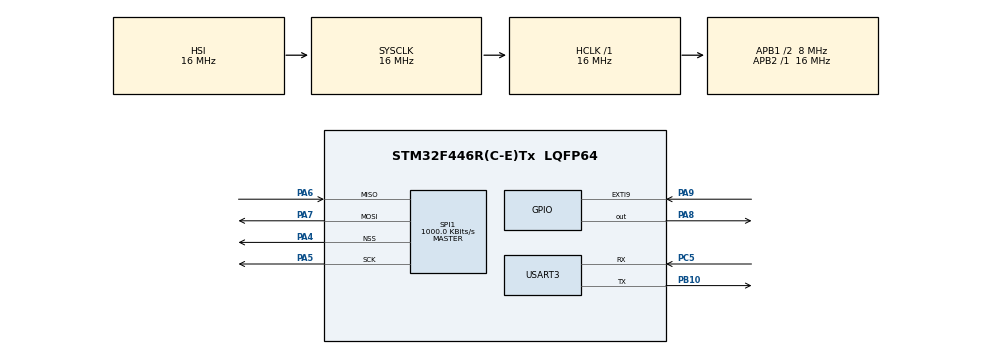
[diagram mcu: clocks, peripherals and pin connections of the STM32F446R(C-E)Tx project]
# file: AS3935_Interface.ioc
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Mcu.Family=STM32F4
Mcu.Name=STM32F446R(C-E)Tx
Mcu.Package=LQFP64
NVIC.EXTI9_5_IRQn=true\:0\:0\:false\:false\:true\:true\:true
NVIC.PriorityGroup=NVIC_PRIORITYGROUP_0
PA13.GPIO_Label=TMS
PA13.Mode=Serial_Wire
PA13.Signal=SYS_JTMS-SWDIO
PA14.GPIO_Label=TCK
PA14.Mode=Serial_Wire
PA14.Signal=SYS_JTCK-SWCLK
PA2.GPIO_Label=USART_TX
PA2.Signal=USART2_TX
PA3.GPIO_Label=USART_RX
PA3.Signal=USART2_RX
PA4.Mode=NSS_Signal_Hard_Output
PA4.Signal=SPI1_NSS
PA5.Mode=Full_Duplex_Master
PA5.Signal=SPI1_SCK
PA6.Mode=Full_Duplex_Master
PA6.Signal=SPI1_MISO
PA7.Mode=Full_Duplex_Master
PA7.Signal=SPI1_MOSI
PA8.Signal=GPIO_Output
PA9.GPIO_PuPd=GPIO_PULLDOWN
PA9.Signal=GPXTI9
PB10.Mode=Asynchronous
PB10.Signal=USART3_TX
PB3.GPIO_Label=SWO
PB3.Signal=SYS_JTDO-SWO
PC14-OSC32_IN.Mode=LSE-External-Oscillator
PC14-OSC32_IN.Signal=RCC_OSC32_IN
PC15-OSC32_OUT.Mode=LSE-External-Oscillator
PC15-OSC32_OUT.Signal=RCC_OSC32_OUT
PC5.Mode=Asynchronous
PC5.Signal=USART3_RX
PH0-OSC_IN.Mode=HSE-External-Oscillator
PH0-OSC_IN.Signal=RCC_OSC_IN
PH1-OSC_OUT.Mode=HSE-External-Oscillator
PH1-OSC_OUT.Signal=RCC_OSC_OUT
ProjectManager.HeapSize=0x200
ProjectManager.StackSize=0x400
ProjectManager.TargetToolchain=STM32CubeIDE
RCC.48MHZClocksFreq_Value=84000000
RCC.AHBFreq_Value=16000000
RCC.APB1CLKDivider=RCC_HCLK_DIV2
RCC.APB1Freq_Value=8000000
RCC.APB1TimFreq_Value=16000000
RCC.APB2Freq_Value=16000000
RCC.APB2TimFreq_Value=16000000
RCC.CortexFreq_Value=16000000
RCC.FLatency-AdvancedSettings=FLASH_LATENCY_0
RCC.HCLKFreq_Value=16000000
RCC.HSE_VALUE=8000000
RCC.HSI_VALUE=16000000
RCC.PLLN=336
RCC.PLLP=RCC_PLLP_DIV4
RCC.SYSCLKFreq_VALUE=16000000
RCC.USBFreq_Value=168000000
RCC.VCOOutputFreq_Value=336000000
SPI1.BaudRatePrescaler=SPI_BAUDRATEPRESCALER_16
SPI1.CLKPhase=SPI_PHASE_2EDGE
SPI1.CalculateBaudRate=1000.0 KBits/s
SPI1.Direction=SPI_DIRECTION_2LINES
SPI1.Mode=SPI_MODE_MASTER
SPI1.VirtualNSS=VM_NSSHARD
SPI1.VirtualType=VM_MASTER
USART3.VirtualMode=VM_ASYNC
board=NUCLEO-F446RE

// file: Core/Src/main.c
#include "main.h"

#include "AS3935_driver.h"

//AS3935 USER VALUES
#define IRQ_PIN			GPIO_PIN_9
#define IRQ_PORT		GPIOA

#define LED_IRQ_PIN		GPIO_PIN_8
#define LED_IRQ_PORT	GPIOA

uint8_t ln_flag = 0;

SPI_HandleTypeDef hspi1;

UART_HandleTypeDef huart3;

void SystemClock_Config(void);
static void MX_GPIO_Init(void);
static void MX_SPI1_Init(void);
static void MX_USART3_UART_Init(void);
void HAL_GPIO_EXTI_Callback(uint16_t GPIO_Pin);

#if DEBUG_SH
extern void initialise_monitor_handles();
#endif

int main(void)
{
  /* USER CODE BEGIN 1 */
	#if DEBUG_SH
	initialise_monitor_handles();
	printf("AS3935 LIGHTNING DETECTOR\n");
	#endif
  /* USER CODE END 1 */

  /* MCU Configuration--------------------------------------------------------*/

  /* Reset of all peripherals, Initializes the Flash interface and the Systick. */
  HAL_Init();

  /* Configure the system clock */
  SystemClock_Config();

  /* Initialize all configured peripherals */
  MX_GPIO_Init();
  MX_SPI1_Init();
  MX_USART3_UART_Init();

  while (1)
  {

  }

}

void SystemClock_Config(void)
{
  RCC_OscInitTypeDef RCC_OscInitStruct = {0};
  RCC_ClkInitTypeDef RCC_ClkInitStruct = {0};

  /** Configure the main internal regulator output voltage
  */
  __HAL_RCC_PWR_CLK_ENABLE();
  __HAL_PWR_VOLTAGESCALING_CONFIG(PWR_REGULATOR_VOLTAGE_SCALE3);
  /** Initializes the CPU, AHB and APB busses clocks
  */
  RCC_OscInitStruct.OscillatorType = RCC_OSCILLATORTYPE_HSI;
  RCC_OscInitStruct.HSIState = RCC_HSI_ON;
  RCC_OscInitStruct.HSICalibrationValue = RCC_HSICALIBRATION_DEFAULT;
  RCC_OscInitStruct.PLL.PLLState = RCC_PLL_NONE;
  if (HAL_RCC_OscConfig(&RCC_OscInitStruct) != HAL_OK)
  {
    Error_Handler();
  }
  /** Initializes the CPU, AHB and APB busses clocks
  */
  RCC_ClkInitStruct.ClockType = RCC_CLOCKTYPE_HCLK|RCC_CLOCKTYPE_SYSCLK
                              |RCC_CLOCKTYPE_PCLK1|RCC_CLOCKTYPE_PCLK2;
  RCC_ClkInitStruct.SYSCLKSource = RCC_SYSCLKSOURCE_HSI;
  RCC_ClkInitStruct.AHBCLKDivider = RCC_SYSCLK_DIV1;
  RCC_ClkInitStruct.APB1CLKDivider = RCC_HCLK_DIV2;
  RCC_ClkInitStruct.APB2CLKDivider = RCC_HCLK_DIV1;

  if (HAL_RCC_ClockConfig(&RCC_ClkInitStruct, FLASH_LATENCY_0) != HAL_OK)
  {
    Error_Handler();
  }
}

static void MX_SPI1_Init(void)
{

  hspi1.Instance = SPI1;
  hspi1.Init.Mode = SPI_MODE_MASTER;
  hspi1.Init.Direction = SPI_DIRECTION_2LINES;
  hspi1.Init.DataSize = SPI_DATASIZE_8BIT;
  hspi1.Init.CLKPolarity = SPI_POLARITY_LOW;
  hspi1.Init.CLKPhase = SPI_PHASE_2EDGE;
  hspi1.Init.NSS = SPI_NSS_HARD_OUTPUT;
  hspi1.Init.BaudRatePrescaler = SPI_BAUDRATEPRESCALER_16;
  hspi1.Init.FirstBit = SPI_FIRSTBIT_MSB;
  hspi1.Init.TIMode = SPI_TIMODE_DISABLE;
  hspi1.Init.CRCCalculation = SPI_CRCCALCULATION_DISABLE;
  hspi1.Init.CRCPolynomial = 10;
  if (HAL_SPI_Init(&hspi1) != HAL_OK)
  {
    Error_Handler();
  }

}

static void MX_USART3_UART_Init(void)
{

  huart3.Instance = USART3;
  huart3.Init.BaudRate = 115200;
  huart3.Init.WordLength = UART_WORDLENGTH_8B;
  huart3.Init.StopBits = UART_STOPBITS_1;
  huart3.Init.Parity = UART_PARITY_NONE;
  huart3.Init.Mode = UART_MODE_TX_RX;
  huart3.Init.HwFlowCtl = UART_HWCONTROL_NONE;
  huart3.Init.OverSampling = UART_OVERSAMPLING_16;
  if (HAL_UART_Init(&huart3) != HAL_OK)
  {
    Error_Handler();
  }

}

static void MX_GPIO_Init(void)
{
  GPIO_InitTypeDef GPIO_InitStruct = {0};

  /* GPIO Ports Clock Enable */
  __HAL_RCC_GPIOC_CLK_ENABLE();
  __HAL_RCC_GPIOH_CLK_ENABLE();
  __HAL_RCC_GPIOA_CLK_ENABLE();
  __HAL_RCC_GPIOB_CLK_ENABLE();

  /*Configure GPIO pin Output Level */
  HAL_GPIO_WritePin(GPIOA, GPIO_PIN_8, GPIO_PIN_RESET);

  /*Configure GPIO pins : USART_TX_Pin USART_RX_Pin */
  GPIO_InitStruct.Pin = USART_TX_Pin|USART_RX_Pin;
  GPIO_InitStruct.Mode = GPIO_MODE_AF_PP;
  GPIO_InitStruct.Pull = GPIO_NOPULL;
  GPIO_InitStruct.Speed = GPIO_SPEED_FREQ_VERY_HIGH;
  GPIO_InitStruct.Alternate = GPIO_AF7_USART2;
  HAL_GPIO_Init(GPIOA, &GPIO_InitStruct);

  /*Configure GPIO pin : PA8 */
  GPIO_InitStruct.Pin = GPIO_PIN_8;
  GPIO_InitStruct.Mode = GPIO_MODE_OUTPUT_PP;
  GPIO_InitStruct.Pull = GPIO_NOPULL;
  GPIO_InitStruct.Speed = GPIO_SPEED_FREQ_LOW;
  HAL_GPIO_Init(GPIOA, &GPIO_InitStruct);

  /*Configure GPIO pin : PA9 */
  GPIO_InitStruct.Pin = GPIO_PIN_9;
  GPIO_InitStruct.Mode = GPIO_MODE_IT_RISING;
  GPIO_InitStruct.Pull = GPIO_PULLDOWN;
  HAL_GPIO_Init(GPIOA, &GPIO_InitStruct);

  /* EXTI interrupt init*/
  HAL_NVIC_SetPriority(EXTI9_5_IRQn, 0, 0);
  HAL_NVIC_EnableIRQ(EXTI9_5_IRQn);

}

void HAL_GPIO_EXTI_Callback(uint16_t GPIO_Pin){
	if(GPIO_Pin == GPIO_PIN_9){
		HAL_GPIO_WritePin(GPIOA, GPIO_PIN_8, GPIO_PIN_SET);
		ln_flag = read_ln_data();
		HAL_GPIO_WritePin(GPIOA, GPIO_PIN_8, GPIO_PIN_RESET);
	}
}

void Error_Handler(void)
{

}
